# S1C31W74 register map
Vendor: Epson; Series: S1C31W74; File version: 1.11
CPU: CM0PLUS r0p1, little endian, MPU, no FPU, VTOR, 2 interrupt priority bits
Registers are 16-bit, read-write, reset 0x0 unless marked. A register's access mark holds for its fields unless they carry their own. Offsets are from the block's base; [hi:lo] are bit positions; 'fields as' and 'values as' point back to an identical list.

## RTCA — Real-time clock control
Base 0x400000C0
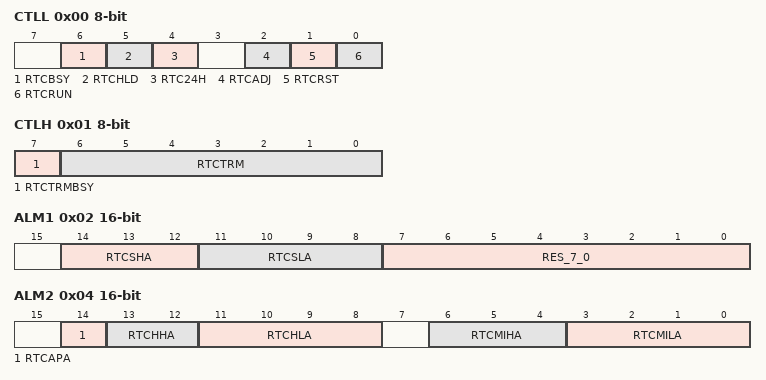
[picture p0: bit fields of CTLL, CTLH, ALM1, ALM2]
0x00 CTLL 8-bit — Control Register
  [6] RTCBSY ro — Counter Busy flag
    0=IDLE (Idle (ready to rewrite real-time clock counter)); 1=BUSY (In count-up operation)
  [5] RTCHLD — Counter Hold control
    0=NORMAL (Normal operation); 1=HALT (Halt real-time clock counter count-up operation)
  [4] RTC24H — 24H/12H Mode Select
    0=12H (12H mode); 1=24H (24H mode)
  [2] RTCADJ write-1-sets — 30 second adjustment
    on write: 0=NON (No effect); 1=ADJUST (Execute 30-second correction) | on read: 0=STOPPED (30-second correction has finished (Normal operation)); 1=RUNNING (30-second correction is executing)
  [1] RTCRST write-1-sets — Software reset
    on write: 0=NON (No effect); 1=RESET | on read: 0=STOPPED (Reset has finished (Normal operation)); 1=RUNNING (Reset is being executed)
  [0] RTCRUN — Counter run/stop control
    0=STOP (Idle/stop control); 1=RUN (Running/start control)
0x01 CTLH 8-bit — Control Register
  [7] RTCTRMBSY ro — Trimming busy flag
    0=IDLE (Theoretical regulation has finished (or not executed)); 1=BUSY (Theoretical regulation is executing)
  [6:0] RTCTRM wo — Theoretical regulation trimming value (2's complement value in 1/256 second)
0x02 ALM1 — Second Alarm Register
  [14:12] RTCSHA range 0..5 — 10 second counter for Alarm (in BCD code)
  [11:8] RTCSLA range 0..9 — 1 second counter for Alarm (in BCD code)
  [7:0] RES_7_0 ro — Reserved bits
0x04 ALM2 — Hour/Minute Alarm Register
  [14] RTCAPA — AM/PM indicator for Alarm
    0=AM; 1=PM
  [13:12] RTCHHA range 0..2 — 10 hour counter for Alarm (in BCD code)
  [11:8] RTCHLA range 0..9 — 1 hour counter for Alarm (in BCD code)
  [6:4] RTCMIHA range 0..5 — 10 minute counter for Alarm (in BCD code)
  [3:0] RTCMILA range 0..9 — 1 minute counter for Alarm (in BCD code)
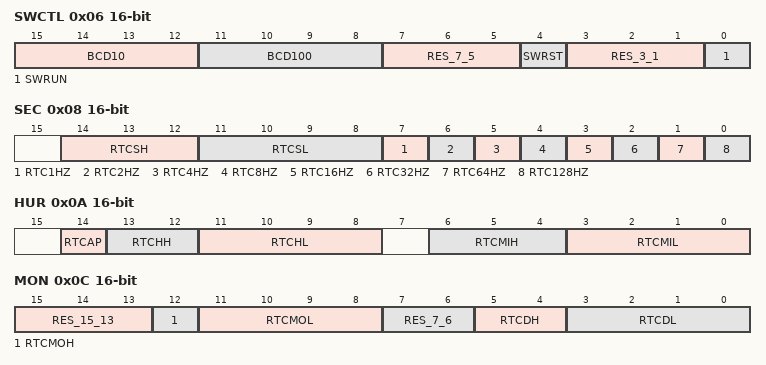
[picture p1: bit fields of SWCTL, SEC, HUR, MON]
0x06 SWCTL — Stopwatch Control Register
  [15:12] BCD10 ro range 0..9 — 1/10 sec BCD counter value
  [11:8] BCD100 ro range 0..9 — 1/100 sec BCD counter value
  [7:5] RES_7_5 ro — Reserved bits
  [4] SWRST wo write-1-sets — Stopwatch counter reset
    0=NON (No effect); 1=RESET
  [3:1] RES_3_1 ro — Reserved bits
  [0] SWRUN — Stopwatch counter run/stop control
    0=STOP (Idle/stop control); 1=RUN (Running/start control)
0x08 SEC — Second/1Hz Register
  [14:12] RTCSH range 0..5 — 10 second counter (in BCD code)
  [11:8] RTCSL range 0..9 — 1 second counter (in BCD code)
  [7] RTC1HZ ro — 1 Hz
  [6] RTC2HZ ro — 2 Hz
  [5] RTC4HZ ro — 4 Hz
  [4] RTC8HZ ro — 8 Hz
  [3] RTC16HZ ro — 16 Hz
  [2] RTC32HZ ro — 32 Hz
  [1] RTC64HZ ro — 64 Hz
  [0] RTC128HZ ro — 128 Hz
0x0A HUR — Hour/Minute Register
  [14] RTCAP — AM/PM indicator
    0=AM; 1=PM
  [13:12] RTCHH range 0..2 — 10 hour counter (in BCD code)
  [11:8] RTCHL range 0..9 — 1 hour counter (in BCD code)
  [6:4] RTCMIH range 0..5 — 10 minute counter (in BCD code)
  [3:0] RTCMIL range 0..9 — 1 minute counter (in BCD code)
0x0C MON — Month/Day Register
  [15:13] RES_15_13 ro — Reserved bits
  [12] RTCMOH — 10 month counter (in BCD code)
  [11:8] RTCMOL range 0..9 — 1 month counter (in BCD code)
  [7:6] RES_7_6 ro — Reserved bits
  [5:4] RTCDH — 10 day counter (in BCD code)
  [3:0] RTCDL range 0..9 — 1 day counter (in BCD code)
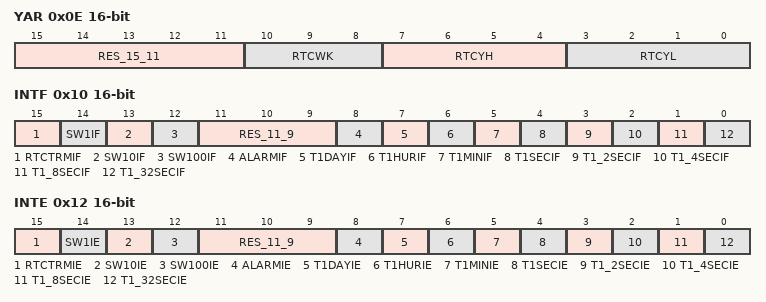
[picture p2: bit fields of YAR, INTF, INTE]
0x0E YAR — Year/Week Register
  [15:11] RES_15_11 ro — Reserved bits
  [10:8] RTCWK — Day of week counter
    0=SUN (Sunday); 1=MON (Monday); 2=TUE (Tuesday); 3=WED (Wednesday); 4=THU (Thursday); 5=FRI (Friday); 6=SAT (Saturday)
  [7:4] RTCYH range 0..9 — 10 year counter (in BCD code)
  [3:0] RTCYL range 0..9 — 1 year counter (in BCD code)
0x10 INTF — Interrupt Flag Register
  [15] RTCTRMIF ro write-1-clears — Theoretical regulation interrupt flag
    0=NOT_OCCURED (No cause of interrupt occurred); 1=OCCURED (Cause of interrupt occurred)
  [14] SW1IF ro write-1-clears — 1 Hz interrupt flag
    values as RTCTRMIF
  [13] SW10IF ro write-1-clears — 10 Hz interrupt flag
    values as RTCTRMIF
  [12] SW100IF ro write-1-clears — 100 Hz interrupt flag
    values as RTCTRMIF
  [11:9] RES_11_9 ro — Reserved bits
  [8] ALARMIF ro write-1-clears — ALARM interrupt flag
    values as RTCTRMIF
  [7] T1DAYIF ro write-1-clears — 1 day interrupt flag
    values as RTCTRMIF
  [6] T1HURIF ro write-1-clears — 1 hour interrupt flag
    values as RTCTRMIF
  [5] T1MINIF ro write-1-clears — 1 minute interrupt flag
    values as RTCTRMIF
  [4] T1SECIF ro write-1-clears — 1 second interrupt flag
    values as RTCTRMIF
  [3] T1_2SECIF ro write-1-clears — 1/2 second interrupt flag
    values as RTCTRMIF
  [2] T1_4SECIF ro write-1-clears — 1/4 second interrupt flag
    values as RTCTRMIF
  [1] T1_8SECIF ro write-1-clears — 1/8 second interrupt flag
    values as RTCTRMIF
  [0] T1_32SECIF ro write-1-clears — 1/32 second interrupt flag
    values as RTCTRMIF
0x12 INTE — Interrupt Enable Register
  [15] RTCTRMIE — Theoretical regulation interrupt enable
    0=DISABLE; 1=ENABLE
  [14] SW1IE — 1 Hz interrupt enable
    0=DISABLE; 1=ENABLE
  [13] SW10IE — 10 Hz interrupt enable
    0=DISABLE; 1=ENABLE
  [12] SW100IE — 100 Hz interrupt enable
    0=DISABLE; 1=ENABLE
  [11:9] RES_11_9 ro — Reserved bits
  [8] ALARMIE — ALARM interrupt enable
    0=DISABLE; 1=ENABLE
  [7] T1DAYIE — 1 day interrupt enable
    0=DISABLE; 1=ENABLE
  [6] T1HURIE — 1 hour interrupt enable
    0=DISABLE; 1=ENABLE
  [5] T1MINIE — 1 minute interrupt enable
    0=DISABLE; 1=ENABLE
  [4] T1SECIE — 1 second interrupt enable
    0=DISABLE; 1=ENABLE
  [3] T1_2SECIE — 1/2 second interrupt enable
    0=DISABLE; 1=ENABLE
  [2] T1_4SECIE — 1/4 second interrupt enable
    0=DISABLE; 1=ENABLE
  [1] T1_8SECIE — 1/8 second interrupt enable
    0=DISABLE; 1=ENABLE
  [0] T1_32SECIE — 1/32 second interrupt enable
    0=DISABLE; 1=ENABLE
